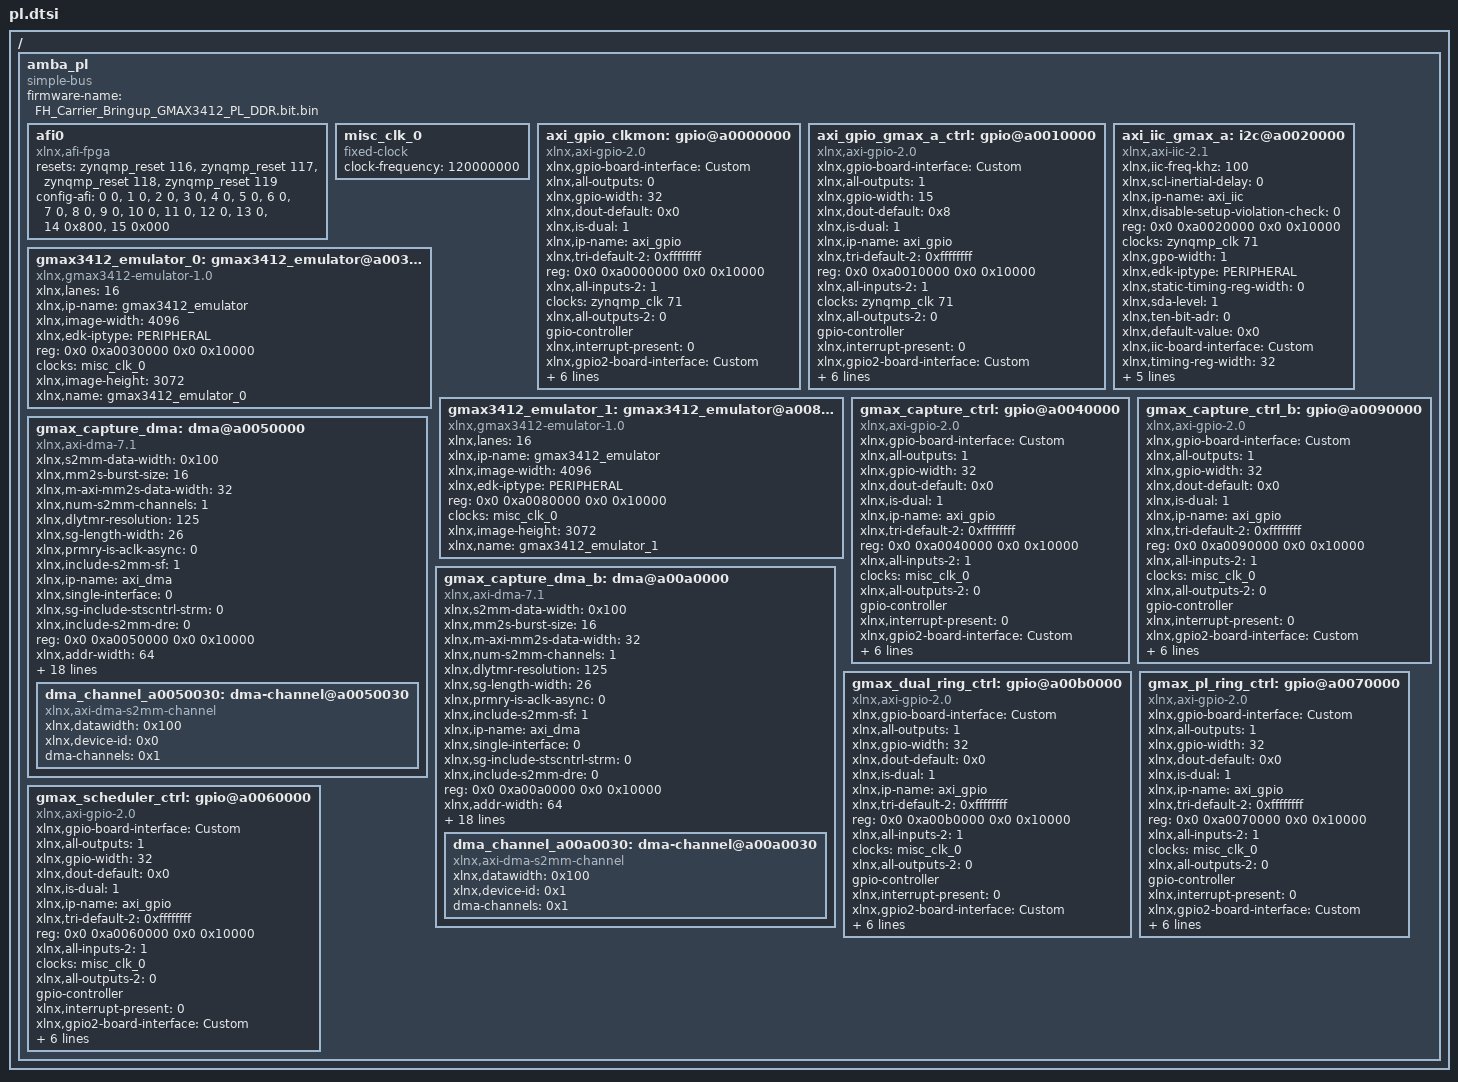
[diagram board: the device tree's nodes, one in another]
/ {
	amba_pl: amba_pl {
		ranges;
		compatible = "simple-bus";
		#address-cells = <2>;
		#size-cells = <2>;
		firmware-name = "FH_Carrier_Bringup_GMAX3412_PL_DDR.bit.bin";
		afi0: afi0 {
			status = "okay";
			compatible = "xlnx,afi-fpga";
			resets = <&zynqmp_reset 116>, <&zynqmp_reset 117>, <&zynqmp_reset 118>, <&zynqmp_reset 119>;
			config-afi = < 0 0>, <1 0>, <2 0>, <3 0>, <4 0>, <5 0>, <6 0>, <7 0>, <8 0>, <9 0>, <10 0>, <11 0>, <12 0>, <13 0>, <14 0x800>, <15 0x000>;
		};
		misc_clk_0: misc_clk_0 {
			compatible = "fixed-clock";
			clock-frequency = <120000000>;
			#clock-cells = <0>;
		};
		axi_gpio_clkmon: gpio@a0000000 {
			xlnx,gpio-board-interface = "Custom";
			compatible = "xlnx,axi-gpio-2.0" , "xlnx,xps-gpio-1.00.a";
			xlnx,all-outputs = <0>;
			#gpio-cells = <2>;
			xlnx,gpio-width = <32>;
			xlnx,dout-default = <0x0>;
			xlnx,is-dual = <1>;
			xlnx,ip-name = "axi_gpio";
			xlnx,tri-default-2 = <0xffffffff>;
			reg = <0x0 0xa0000000 0x0 0x10000>;
			xlnx,all-inputs-2 = <1>;
			clocks = <&zynqmp_clk 71>;
			xlnx,all-outputs-2 = <0>;
			gpio-controller;
			xlnx,interrupt-present = <0>;
			xlnx,gpio2-board-interface = "Custom";
			xlnx,edk-iptype = "PERIPHERAL";
			xlnx,dout-default-2 = <0x0>;
			status = "okay";
			xlnx,gpio2-width = <32>;
			clock-names = "s_axi_aclk";
			xlnx,tri-default = <0xffffffff>;
			xlnx,name = "axi_gpio_clkmon";
			xlnx,all-inputs = <1>;
		};
		axi_gpio_gmax_a_ctrl: gpio@a0010000 {
			xlnx,gpio-board-interface = "Custom";
			compatible = "xlnx,axi-gpio-2.0" , "xlnx,xps-gpio-1.00.a";
			xlnx,all-outputs = <1>;
			#gpio-cells = <2>;
			xlnx,gpio-width = <15>;
			xlnx,dout-default = <0x8>;
			xlnx,is-dual = <1>;
			xlnx,ip-name = "axi_gpio";
			xlnx,tri-default-2 = <0xffffffff>;
			reg = <0x0 0xa0010000 0x0 0x10000>;
			xlnx,all-inputs-2 = <1>;
			clocks = <&zynqmp_clk 71>;
			xlnx,all-outputs-2 = <0>;
			gpio-controller;
			xlnx,interrupt-present = <0>;
			xlnx,gpio2-board-interface = "Custom";
			xlnx,edk-iptype = "PERIPHERAL";
			xlnx,dout-default-2 = <0x0>;
			status = "okay";
			xlnx,gpio2-width = <32>;
			clock-names = "s_axi_aclk";
			xlnx,tri-default = <0xffffffff>;
			xlnx,name = "axi_gpio_gmax_a_ctrl";
			xlnx,all-inputs = <0>;
		};
		axi_iic_gmax_a: i2c@a0020000 {
			xlnx,iic-freq-khz = <100>;
			compatible = "xlnx,axi-iic-2.1" , "xlnx,xps-iic-2.00.a";
			xlnx,scl-inertial-delay = <0>;
			xlnx,ip-name = "axi_iic";
			xlnx,disable-setup-violation-check = <0>;
			reg = <0x0 0xa0020000 0x0 0x10000>;
			clocks = <&zynqmp_clk 71>;
			xlnx,gpo-width = <1>;
			xlnx,edk-iptype = "PERIPHERAL";
			xlnx,static-timing-reg-width = <0>;
			xlnx,sda-level = <1>;
			status = "okay";
			clock-names = "s_axi_aclk";
			xlnx,ten-bit-adr = <0>;
			xlnx,default-value = <0x0>;
			xlnx,iic-board-interface = "Custom";
			xlnx,timing-reg-width = <32>;
			xlnx,iic-freq = <100000>;
			xlnx,smbus-pmbus-host = <0>;
			xlnx,name = "axi_iic_gmax_a";
			xlnx,axi-aclk-freq-mhz = <100>;
			xlnx,sda-inertial-delay = <0>;
		};
		gmax3412_emulator_0: gmax3412_emulator@a0030000 {
			compatible = "xlnx,gmax3412-emulator-1.0";
			status = "okay";
			clock-names = "s_axi_aclk";
			xlnx,lanes = <16>;
			xlnx,ip-name = "gmax3412_emulator";
			xlnx,image-width = <4096>;
			xlnx,edk-iptype = "PERIPHERAL";
			reg = <0x0 0xa0030000 0x0 0x10000>;
			clocks = <&misc_clk_0>;
			xlnx,image-height = <3072>;
			xlnx,name = "gmax3412_emulator_0";
		};
		gmax3412_emulator_1: gmax3412_emulator@a0080000 {
			compatible = "xlnx,gmax3412-emulator-1.0";
			status = "okay";
			clock-names = "s_axi_aclk";
			xlnx,lanes = <16>;
			xlnx,ip-name = "gmax3412_emulator";
			xlnx,image-width = <4096>;
			xlnx,edk-iptype = "PERIPHERAL";
			reg = <0x0 0xa0080000 0x0 0x10000>;
			clocks = <&misc_clk_0>;
			xlnx,image-height = <3072>;
			xlnx,name = "gmax3412_emulator_1";
		};
		gmax_capture_ctrl: gpio@a0040000 {
			xlnx,gpio-board-interface = "Custom";
			compatible = "xlnx,axi-gpio-2.0" , "xlnx,xps-gpio-1.00.a";
			xlnx,all-outputs = <1>;
			#gpio-cells = <2>;
			xlnx,gpio-width = <32>;
			xlnx,dout-default = <0x0>;
			xlnx,is-dual = <1>;
			xlnx,ip-name = "axi_gpio";
			xlnx,tri-default-2 = <0xffffffff>;
			reg = <0x0 0xa0040000 0x0 0x10000>;
			xlnx,all-inputs-2 = <1>;
			clocks = <&misc_clk_0>;
			xlnx,all-outputs-2 = <0>;
			gpio-controller;
			xlnx,interrupt-present = <0>;
			xlnx,gpio2-board-interface = "Custom";
			xlnx,edk-iptype = "PERIPHERAL";
			xlnx,dout-default-2 = <0x0>;
			status = "okay";
			xlnx,gpio2-width = <32>;
			clock-names = "s_axi_aclk";
			xlnx,tri-default = <0xffffffff>;
			xlnx,name = "gmax_capture_ctrl";
			xlnx,all-inputs = <0>;
		};
		gmax_capture_ctrl_b: gpio@a0090000 {
			xlnx,gpio-board-interface = "Custom";
			compatible = "xlnx,axi-gpio-2.0" , "xlnx,xps-gpio-1.00.a";
			xlnx,all-outputs = <1>;
			#gpio-cells = <2>;
			xlnx,gpio-width = <32>;
			xlnx,dout-default = <0x0>;
			xlnx,is-dual = <1>;
			xlnx,ip-name = "axi_gpio";
			xlnx,tri-default-2 = <0xffffffff>;
			reg = <0x0 0xa0090000 0x0 0x10000>;
			xlnx,all-inputs-2 = <1>;
			clocks = <&misc_clk_0>;
			xlnx,all-outputs-2 = <0>;
			gpio-controller;
			xlnx,interrupt-present = <0>;
			xlnx,gpio2-board-interface = "Custom";
			xlnx,edk-iptype = "PERIPHERAL";
			xlnx,dout-default-2 = <0x0>;
			status = "okay";
			xlnx,gpio2-width = <32>;
			clock-names = "s_axi_aclk";
			xlnx,tri-default = <0xffffffff>;
			xlnx,name = "gmax_capture_ctrl_b";
			xlnx,all-inputs = <0>;
		};
		gmax_capture_dma: dma@a0050000 {
			compatible = "xlnx,axi-dma-7.1" , "xlnx,axi-dma-1.00.a";
			xlnx,s2mm-data-width = <0x100>;
			xlnx,mm2s-burst-size = <16>;
			xlnx,m-axi-mm2s-data-width = <32>;
			xlnx,num-s2mm-channels = <1>;
			xlnx,dlytmr-resolution = <125>;
			xlnx,sg-length-width = <26>;
			xlnx,prmry-is-aclk-async = <0>;
			xlnx,include-s2mm-sf = <1>;
			#dma-cells = <1>;
			xlnx,ip-name = "axi_dma";
			xlnx,single-interface = <0>;
			xlnx,sg-include-stscntrl-strm = <0>;
			xlnx,include-s2mm-dre = <0>;
			reg = <0x0 0xa0050000 0x0 0x10000>;
			xlnx,addr-width = <64>;
			xlnx,include-s2mm = <1>;
			clocks = <&misc_clk_0>, <&misc_clk_0>;
			xlnx,s-axis-s2mm-tdata-width = <256>;
			xlnx,micro-dma = <0>;
			xlnx,increase-throughput = <0>;
			xlnx,mm2s-data-width = <0x20>;
			xlnx,addrwidth = <0x40>;
			xlnx,sg-use-stsapp-length = <0>;
			xlnx,m-axis-mm2s-tdata-width = <32>;
			xlnx,edk-iptype = "PERIPHERAL";
			xlnx,s2mm-burst-size = <64>;
			xlnx,m-axi-s2mm-data-width = <256>;
			xlnx,num-mm2s-channels = <1>;
			xlnx,enable-multi-channel = <0>;
			status = "okay";
			xlnx,include-mm2s-sf = <1>;
			clock-names = "m_axi_s2mm_aclk" , "s_axi_lite_aclk";
			xlnx,include-mm2s = <0>;
			xlnx,include-mm2s-dre = <0>;
			xlnx,name = "gmax_capture_dma";
			dma_channel_a0050030: dma-channel@a0050030 {
				xlnx,datawidth = <0x100>;
				xlnx,device-id = <0x0>;
				compatible = "xlnx,axi-dma-s2mm-channel";
				dma-channels = <0x1>;
			};
		};
		gmax_capture_dma_b: dma@a00a0000 {
			compatible = "xlnx,axi-dma-7.1" , "xlnx,axi-dma-1.00.a";
			xlnx,s2mm-data-width = <0x100>;
			xlnx,mm2s-burst-size = <16>;
			xlnx,m-axi-mm2s-data-width = <32>;
			xlnx,num-s2mm-channels = <1>;
			xlnx,dlytmr-resolution = <125>;
			xlnx,sg-length-width = <26>;
			xlnx,prmry-is-aclk-async = <0>;
			xlnx,include-s2mm-sf = <1>;
			#dma-cells = <1>;
			xlnx,ip-name = "axi_dma";
			xlnx,single-interface = <0>;
			xlnx,sg-include-stscntrl-strm = <0>;
			xlnx,include-s2mm-dre = <0>;
			reg = <0x0 0xa00a0000 0x0 0x10000>;
			xlnx,addr-width = <64>;
			xlnx,include-s2mm = <1>;
			clocks = <&misc_clk_0>, <&misc_clk_0>;
			xlnx,s-axis-s2mm-tdata-width = <256>;
			xlnx,micro-dma = <0>;
			xlnx,increase-throughput = <0>;
			xlnx,mm2s-data-width = <0x20>;
			xlnx,addrwidth = <0x40>;
			xlnx,sg-use-stsapp-length = <0>;
			xlnx,m-axis-mm2s-tdata-width = <32>;
			xlnx,edk-iptype = "PERIPHERAL";
			xlnx,s2mm-burst-size = <64>;
			xlnx,m-axi-s2mm-data-width = <256>;
			xlnx,num-mm2s-channels = <1>;
			xlnx,enable-multi-channel = <0>;
			status = "okay";
			xlnx,include-mm2s-sf = <1>;
			clock-names = "m_axi_s2mm_aclk" , "s_axi_lite_aclk";
			xlnx,include-mm2s = <0>;
			xlnx,include-mm2s-dre = <0>;
			xlnx,name = "gmax_capture_dma_b";
			dma_channel_a00a0030: dma-channel@a00a0030 {
				xlnx,datawidth = <0x100>;
				xlnx,device-id = <0x1>;
				compatible = "xlnx,axi-dma-s2mm-channel";
				dma-channels = <0x1>;
			};
		};
		gmax_dual_ring_ctrl: gpio@a00b0000 {
			xlnx,gpio-board-interface = "Custom";
			compatible = "xlnx,axi-gpio-2.0" , "xlnx,xps-gpio-1.00.a";
			xlnx,all-outputs = <1>;
			#gpio-cells = <2>;
			xlnx,gpio-width = <32>;
			xlnx,dout-default = <0x0>;
			xlnx,is-dual = <1>;
			xlnx,ip-name = "axi_gpio";
			xlnx,tri-default-2 = <0xffffffff>;
			reg = <0x0 0xa00b0000 0x0 0x10000>;
			xlnx,all-inputs-2 = <1>;
			clocks = <&misc_clk_0>;
			xlnx,all-outputs-2 = <0>;
			gpio-controller;
			xlnx,interrupt-present = <0>;
			xlnx,gpio2-board-interface = "Custom";
			xlnx,edk-iptype = "PERIPHERAL";
			xlnx,dout-default-2 = <0x0>;
			status = "okay";
			xlnx,gpio2-width = <32>;
			clock-names = "s_axi_aclk";
			xlnx,tri-default = <0xffffffff>;
			xlnx,name = "gmax_dual_ring_ctrl";
			xlnx,all-inputs = <0>;
		};
		gmax_pl_ring_ctrl: gpio@a0070000 {
			xlnx,gpio-board-interface = "Custom";
			compatible = "xlnx,axi-gpio-2.0" , "xlnx,xps-gpio-1.00.a";
			xlnx,all-outputs = <1>;
			#gpio-cells = <2>;
			xlnx,gpio-width = <32>;
			xlnx,dout-default = <0x0>;
			xlnx,is-dual = <1>;
			xlnx,ip-name = "axi_gpio";
			xlnx,tri-default-2 = <0xffffffff>;
			reg = <0x0 0xa0070000 0x0 0x10000>;
			xlnx,all-inputs-2 = <1>;
			clocks = <&misc_clk_0>;
			xlnx,all-outputs-2 = <0>;
			gpio-controller;
			xlnx,interrupt-present = <0>;
			xlnx,gpio2-board-interface = "Custom";
			xlnx,edk-iptype = "PERIPHERAL";
			xlnx,dout-default-2 = <0x0>;
			status = "okay";
			xlnx,gpio2-width = <32>;
			clock-names = "s_axi_aclk";
			xlnx,tri-default = <0xffffffff>;
			xlnx,name = "gmax_pl_ring_ctrl";
			xlnx,all-inputs = <0>;
		};
		gmax_scheduler_ctrl: gpio@a0060000 {
			xlnx,gpio-board-interface = "Custom";
			compatible = "xlnx,axi-gpio-2.0" , "xlnx,xps-gpio-1.00.a";
			xlnx,all-outputs = <1>;
			#gpio-cells = <2>;
			xlnx,gpio-width = <32>;
			xlnx,dout-default = <0x0>;
			xlnx,is-dual = <1>;
			xlnx,ip-name = "axi_gpio";
			xlnx,tri-default-2 = <0xffffffff>;
			reg = <0x0 0xa0060000 0x0 0x10000>;
			xlnx,all-inputs-2 = <1>;
			clocks = <&misc_clk_0>;
			xlnx,all-outputs-2 = <0>;
			gpio-controller;
			xlnx,interrupt-present = <0>;
			xlnx,gpio2-board-interface = "Custom";
			xlnx,edk-iptype = "PERIPHERAL";
			xlnx,dout-default-2 = <0x0>;
			status = "okay";
			xlnx,gpio2-width = <32>;
			clock-names = "s_axi_aclk";
			xlnx,tri-default = <0xffffffff>;
			xlnx,name = "gmax_scheduler_ctrl";
			xlnx,all-inputs = <0>;
		};
	};
};
